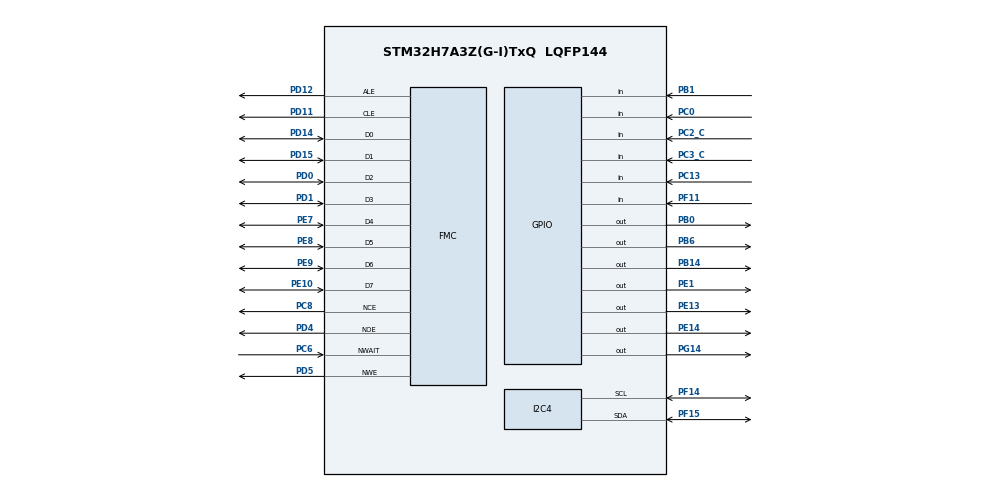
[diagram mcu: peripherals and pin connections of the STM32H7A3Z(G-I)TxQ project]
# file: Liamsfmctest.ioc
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CORTEX_M7.default_mode_Activation=1
Mcu.Family=STM32H7
Mcu.Name=STM32H7A3Z(G-I)TxQ
Mcu.Package=LQFP144
NUCLEO-H7A3ZI-Q.BUTTON=1
NUCLEO-H7A3ZI-Q.LD1=true
NUCLEO-H7A3ZI-Q.LD2=true
NUCLEO-H7A3ZI-Q.LD3=true
NUCLEO-H7A3ZI-Q.VCP=true
NVIC.EXTI15_10_IRQn=true\:0\:0\:false\:false\:true\:false\:true\:true
NVIC.PriorityGroup=NVIC_PRIORITYGROUP_4
PB0.Signal=GPIO_Output
PB1.GPIO_PuPd=GPIO_PULLUP
PB1.Signal=GPIO_Input
PB14.Signal=GPIO_Output
PB6.Signal=GPIO_Output
PC0.GPIO_PuPd=GPIO_PULLUP
PC0.Signal=GPIO_Input
PC13.Signal=GPIO_Input
PC14-OSC32_IN.GPIO_Label=OSC32_IN
PC14-OSC32_IN.Signal=RCC_OSC32_IN
PC15-OSC32_OUT.GPIO_Label=OSC32_OUT
PC15-OSC32_OUT.Signal=RCC_OSC32_OUT
PC2_C.GPIO_PuPd=GPIO_PULLUP
PC2_C.Signal=GPIO_Input
PC3_C.GPIO_PuPd=GPIO_PULLUP
PC3_C.Signal=GPIO_Input
PC6.Signal=FMC_NWAIT
PC8.Mode=NandChipSelect3_1
PC8.Signal=FMC_NCE
PD0.Signal=FMC_D2_DA2
PD1.Signal=FMC_D3_DA3
PD11.Signal=FMC_A16_CLE
PD12.Signal=FMC_A17_ALE
PD14.Signal=FMC_D0_DA0
PD15.Signal=FMC_D1_DA1
PD4.Signal=FMC_NOE
PD5.Signal=FMC_NWE
PD8.Signal=USART3_TX
PD9.Signal=USART3_RX
PE1.Signal=GPIO_Output
PE10.Signal=FMC_D7_DA7
PE13.Signal=GPIO_Output
PE14.Signal=GPIO_Output
PE7.Signal=FMC_D4_DA4
PE8.Signal=FMC_D5_DA5
PE9.Signal=FMC_D6_DA6
PF11.GPIO_PuPd=GPIO_PULLUP
PF11.Signal=GPIO_Input
PF14.Mode=I2C
PF14.Signal=I2C4_SCL
PF15.Mode=I2C
PF15.Signal=I2C4_SDA
PG14.Signal=GPIO_Output
PH0-OSC_IN.GPIO_Label=PH0-MCU
PH0-OSC_IN.Signal=RCC_OSC_IN
PH1-OSC_OUT.GPIO_Label=PH1-MCU
PH1-OSC_OUT.Signal=RCC_OSC_OUT
ProjectManager.HeapSize=0x200
ProjectManager.StackSize=0x400
ProjectManager.TargetToolchain=STM32CubeIDE
RCC.ADCFreq_Value=129000000
RCC.APB1Freq_Value=64000000
RCC.APB2Freq_Value=64000000
RCC.APB3Freq_Value=64000000
RCC.APB4Freq_Value=64000000
RCC.CortexFreq_Value=64000000
RCC.DIVM1=4
RCC.DIVM3=1
RCC.DIVN1=8
RCC.DIVN3=24
RCC.DIVQ1=4
RCC.HCLKFreq_Value=64000000
RCC.HSE_VALUE=8000000
RCC.PLLFRACN=0
RCC.PWR_Regulator_Voltage_Scale=PWR_REGULATOR_VOLTAGE_SCALE0
RCC.SYSCLKFreq_VALUE=64000000
RCC.SYSCLKSource=RCC_SYSCLKSOURCE_PLLCLK
RCC.SupplySource=PWR_DIRECT_SMPS_SUPPLY
RCC.USBCLockSelection=RCC_USBCLKSOURCE_HSI48
RCC.USBFreq_Value=48000000
SH.FMC_A16_CLE.0=FMC_CLE,8b-dmux1
SH.FMC_A17_ALE.0=FMC_ALE,8b-dmux1
SH.FMC_D0_DA0.0=FMC_D0,8b-dmux1
SH.FMC_D1_DA1.0=FMC_D1,8b-dmux1
SH.FMC_D2_DA2.0=FMC_D2,8b-dmux1
SH.FMC_D3_DA3.0=FMC_D3,8b-dmux1
SH.FMC_D4_DA4.0=FMC_D4,8b-dmux1
SH.FMC_D5_DA5.0=FMC_D5,8b-dmux1
SH.FMC_D6_DA6.0=FMC_D6,8b-dmux1
SH.FMC_D7_DA7.0=FMC_D7,8b-dmux1
SH.FMC_NOE.0=FMC_NOE,8b-dmux1
SH.FMC_NWAIT.0=FMC_NWAIT,Wait1
SH.FMC_NWE.0=FMC_NWE,8b-dmux1
VP_MEMORYMAP_VS_MEMORYMAP.Mode=CurAppReg
VP_NUCLEO-H7A3ZI-Q_VS_BSP_COMMON.Mode=COMMON
board=NUCLEO-H7A3ZI-Q

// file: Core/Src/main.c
/* USER CODE BEGIN Header */
/**
  ******************************************************************************
  * @file           : main.c
  * @brief          : Main program body
  ******************************************************************************
  * @attention
  *
  * Copyright (c) 2024 STMicroelectronics.
  * All rights reserved.
  *
  * This software is licensed under terms that can be found in the LICENSE file
  * in the root directory of this software component.
  * If no LICENSE file comes with this software, it is provided AS-IS.
  *
  ******************************************************************************
  */
/* USER CODE END Header */
#include "main.h"

/* USER CODE BEGIN Includes */
#define FLASH_COMMON_BANK_ADDR            0x80000000
#define FLASH_ATTRIBUTE_BANK_ADDR        0x88000000
#define FLASH_DATA_OFFSET                0x00000000
#define FLASH_COMMAND_OFFSET            0x01000000
#define FLASH_ADDRESS_OFFSET            0x02000000
/* USER CODE END Includes */

COM_InitTypeDef BspCOMInit;

I2C_HandleTypeDef hi2c4;

NAND_HandleTypeDef hnand1;

void SystemClock_Config(void);
static void MPU_Config(void);
static void MX_GPIO_Init(void);
static void MX_I2C4_Init(void);
static void MX_FMC_Init(void);

int main(void)
{

  /* MPU Configuration--------------------------------------------------------*/
  MPU_Config();

  /* MCU Configuration--------------------------------------------------------*/

  /* Reset of all peripherals, Initializes the Flash interface and the Systick. */
  HAL_Init();

  /* Configure the system clock */
  SystemClock_Config();

  /* Initialize all configured peripherals */
  MX_GPIO_Init();
  MX_I2C4_Init();
  MX_FMC_Init();

  /* Initialize leds */
  BSP_LED_Init(LED_GREEN);
  BSP_LED_Init(LED_YELLOW);
  BSP_LED_Init(LED_RED);

  /* Initialize USER push-button, will be used to trigger an interrupt each time it's pressed.*/
  BSP_PB_Init(BUTTON_USER, BUTTON_MODE_EXTI);

  /* Initialize COM1 port (115200, 8 bits (7-bit data + 1 stop bit), no parity */
  BspCOMInit.BaudRate   = 115200;
  BspCOMInit.WordLength = COM_WORDLENGTH_8B;
  BspCOMInit.StopBits   = COM_STOPBITS_1;
  BspCOMInit.Parity     = COM_PARITY_NONE;
  BspCOMInit.HwFlowCtl  = COM_HWCONTROL_NONE;
  if (BSP_COM_Init(COM1, &BspCOMInit) != BSP_ERROR_NONE)
  {
    Error_Handler();
  }

  /* Infinite loop */
  /* USER CODE BEGIN WHILE */
  while (1)
  {
	  *(__IO uint32_t*) (FLASH_COMMON_BANK_ADDR + FLASH_DATA_OFFSET) = 42;
    /* USER CODE END WHILE */

  }
}

void SystemClock_Config(void)
{
  RCC_OscInitTypeDef RCC_OscInitStruct = {0};
  RCC_ClkInitTypeDef RCC_ClkInitStruct = {0};

  /*AXI clock gating */
  RCC->CKGAENR = 0xFFFFFFFF;

  /** Supply configuration update enable
  */
  HAL_PWREx_ConfigSupply(PWR_DIRECT_SMPS_SUPPLY);

  /** Configure the main internal regulator output voltage
  */
  __HAL_PWR_VOLTAGESCALING_CONFIG(PWR_REGULATOR_VOLTAGE_SCALE0);

  while(!__HAL_PWR_GET_FLAG(PWR_FLAG_VOSRDY)) {}

  /** Initializes the RCC Oscillators according to the specified parameters
  * in the RCC_OscInitTypeDef structure.
  */
  RCC_OscInitStruct.OscillatorType = RCC_OSCILLATORTYPE_HSI;
  RCC_OscInitStruct.HSIState = RCC_HSI_DIV1;
  RCC_OscInitStruct.HSICalibrationValue = 64;
  RCC_OscInitStruct.PLL.PLLState = RCC_PLL_ON;
  RCC_OscInitStruct.PLL.PLLSource = RCC_PLLSOURCE_HSI;
  RCC_OscInitStruct.PLL.PLLM = 4;
  RCC_OscInitStruct.PLL.PLLN = 8;
  RCC_OscInitStruct.PLL.PLLP = 2;
  RCC_OscInitStruct.PLL.PLLQ = 4;
  RCC_OscInitStruct.PLL.PLLR = 2;
  RCC_OscInitStruct.PLL.PLLRGE = RCC_PLL1VCIRANGE_3;
  RCC_OscInitStruct.PLL.PLLVCOSEL = RCC_PLL1VCOWIDE;
  RCC_OscInitStruct.PLL.PLLFRACN = 0;
  if (HAL_RCC_OscConfig(&RCC_OscInitStruct) != HAL_OK)
  {
    Error_Handler();
  }

  /** Initializes the CPU, AHB and APB buses clocks
  */
  RCC_ClkInitStruct.ClockType = RCC_CLOCKTYPE_HCLK|RCC_CLOCKTYPE_SYSCLK
                              |RCC_CLOCKTYPE_PCLK1|RCC_CLOCKTYPE_PCLK2
                              |RCC_CLOCKTYPE_D3PCLK1|RCC_CLOCKTYPE_D1PCLK1;
  RCC_ClkInitStruct.SYSCLKSource = RCC_SYSCLKSOURCE_PLLCLK;
  RCC_ClkInitStruct.SYSCLKDivider = RCC_SYSCLK_DIV1;
  RCC_ClkInitStruct.AHBCLKDivider = RCC_HCLK_DIV1;
  RCC_ClkInitStruct.APB3CLKDivider = RCC_APB3_DIV1;
  RCC_ClkInitStruct.APB1CLKDivider = RCC_APB1_DIV1;
  RCC_ClkInitStruct.APB2CLKDivider = RCC_APB2_DIV1;
  RCC_ClkInitStruct.APB4CLKDivider = RCC_APB4_DIV1;

  if (HAL_RCC_ClockConfig(&RCC_ClkInitStruct, FLASH_LATENCY_1) != HAL_OK)
  {
    Error_Handler();
  }
}

static void MX_I2C4_Init(void)
{

  hi2c4.Instance = I2C4;
  hi2c4.Init.Timing = 0x10707DBC;
  hi2c4.Init.OwnAddress1 = 0;
  hi2c4.Init.AddressingMode = I2C_ADDRESSINGMODE_7BIT;
  hi2c4.Init.DualAddressMode = I2C_DUALADDRESS_DISABLE;
  hi2c4.Init.OwnAddress2 = 0;
  hi2c4.Init.OwnAddress2Masks = I2C_OA2_NOMASK;
  hi2c4.Init.GeneralCallMode = I2C_GENERALCALL_DISABLE;
  hi2c4.Init.NoStretchMode = I2C_NOSTRETCH_DISABLE;
  if (HAL_I2C_Init(&hi2c4) != HAL_OK)
  {
    Error_Handler();
  }

  /** Configure Analogue filter
  */
  if (HAL_I2CEx_ConfigAnalogFilter(&hi2c4, I2C_ANALOGFILTER_ENABLE) != HAL_OK)
  {
    Error_Handler();
  }

  /** Configure Digital filter
  */
  if (HAL_I2CEx_ConfigDigitalFilter(&hi2c4, 0) != HAL_OK)
  {
    Error_Handler();
  }

}

/* FMC initialization function */
static void MX_FMC_Init(void)
{

  FMC_NAND_PCC_TimingTypeDef ComSpaceTiming = {0};
  FMC_NAND_PCC_TimingTypeDef AttSpaceTiming = {0};

  /** Perform the NAND1 memory initialization sequence
  */
  hnand1.Instance = FMC_NAND_DEVICE;
  /* hnand1.Init */
  hnand1.Init.NandBank = FMC_NAND_BANK3;
  hnand1.Init.Waitfeature = FMC_NAND_WAIT_FEATURE_ENABLE;
  hnand1.Init.MemoryDataWidth = FMC_NAND_MEM_BUS_WIDTH_8;
  hnand1.Init.EccComputation = FMC_NAND_ECC_DISABLE;
  hnand1.Init.ECCPageSize = FMC_NAND_ECC_PAGE_SIZE_256BYTE;
  hnand1.Init.TCLRSetupTime = 0;
  hnand1.Init.TARSetupTime = 0;
  /* hnand1.Config */
  hnand1.Config.PageSize = 0;
  hnand1.Config.SpareAreaSize = 0;
  hnand1.Config.BlockSize = 0;
  hnand1.Config.BlockNbr = 0;
  hnand1.Config.PlaneNbr = 0;
  hnand1.Config.PlaneSize = 0;
  hnand1.Config.ExtraCommandEnable = DISABLE;
  /* ComSpaceTiming */
  ComSpaceTiming.SetupTime = 252;
  ComSpaceTiming.WaitSetupTime = 252;
  ComSpaceTiming.HoldSetupTime = 252;
  ComSpaceTiming.HiZSetupTime = 252;
  /* AttSpaceTiming */
  AttSpaceTiming.SetupTime = 252;
  AttSpaceTiming.WaitSetupTime = 252;
  AttSpaceTiming.HoldSetupTime = 252;
  AttSpaceTiming.HiZSetupTime = 252;

  if (HAL_NAND_Init(&hnand1, &ComSpaceTiming, &AttSpaceTiming) != HAL_OK)
  {
    Error_Handler( );
  }

}

static void MX_GPIO_Init(void)
{
  GPIO_InitTypeDef GPIO_InitStruct = {0};

  /* GPIO Ports Clock Enable */
  __HAL_RCC_GPIOC_CLK_ENABLE();
  __HAL_RCC_GPIOH_CLK_ENABLE();
  __HAL_RCC_GPIOB_CLK_ENABLE();
  __HAL_RCC_GPIOF_CLK_ENABLE();
  __HAL_RCC_GPIOE_CLK_ENABLE();
  __HAL_RCC_GPIOD_CLK_ENABLE();
  __HAL_RCC_GPIOG_CLK_ENABLE();

  /*Configure GPIO pin Output Level */
  HAL_GPIO_WritePin(GPIOE, GPIO_PIN_13|GPIO_PIN_14, GPIO_PIN_RESET);

  /*Configure GPIO pin Output Level */
  HAL_GPIO_WritePin(GPIOG, GPIO_PIN_14, GPIO_PIN_RESET);

  /*Configure GPIO pin Output Level */
  HAL_GPIO_WritePin(GPIOB, GPIO_PIN_6, GPIO_PIN_RESET);

  /*Configure GPIO pins : PC0 PC2 PC3 */
  GPIO_InitStruct.Pin = GPIO_PIN_0|GPIO_PIN_2|GPIO_PIN_3;
  GPIO_InitStruct.Mode = GPIO_MODE_INPUT;
  GPIO_InitStruct.Pull = GPIO_PULLUP;
  HAL_GPIO_Init(GPIOC, &GPIO_InitStruct);

  /*Configure GPIO pin : PB1 */
  GPIO_InitStruct.Pin = GPIO_PIN_1;
  GPIO_InitStruct.Mode = GPIO_MODE_INPUT;
  GPIO_InitStruct.Pull = GPIO_PULLUP;
  HAL_GPIO_Init(GPIOB, &GPIO_InitStruct);

  /*Configure GPIO pin : PF11 */
  GPIO_InitStruct.Pin = GPIO_PIN_11;
  GPIO_InitStruct.Mode = GPIO_MODE_INPUT;
  GPIO_InitStruct.Pull = GPIO_PULLUP;
  HAL_GPIO_Init(GPIOF, &GPIO_InitStruct);

  /*Configure GPIO pins : PE13 PE14 */
  GPIO_InitStruct.Pin = GPIO_PIN_13|GPIO_PIN_14;
  GPIO_InitStruct.Mode = GPIO_MODE_OUTPUT_PP;
  GPIO_InitStruct.Pull = GPIO_NOPULL;
  GPIO_InitStruct.Speed = GPIO_SPEED_FREQ_LOW;
  HAL_GPIO_Init(GPIOE, &GPIO_InitStruct);

  /*Configure GPIO pin : PG14 */
  GPIO_InitStruct.Pin = GPIO_PIN_14;
  GPIO_InitStruct.Mode = GPIO_MODE_OUTPUT_PP;
  GPIO_InitStruct.Pull = GPIO_NOPULL;
  GPIO_InitStruct.Speed = GPIO_SPEED_FREQ_LOW;
  HAL_GPIO_Init(GPIOG, &GPIO_InitStruct);

  /*Configure GPIO pin : PB6 */
  GPIO_InitStruct.Pin = GPIO_PIN_6;
  GPIO_InitStruct.Mode = GPIO_MODE_OUTPUT_PP;
  GPIO_InitStruct.Pull = GPIO_NOPULL;
  GPIO_InitStruct.Speed = GPIO_SPEED_FREQ_LOW;
  HAL_GPIO_Init(GPIOB, &GPIO_InitStruct);

}

 /* MPU Configuration */

void MPU_Config(void)
{
  MPU_Region_InitTypeDef MPU_InitStruct = {0};

  /* Disables the MPU */
  HAL_MPU_Disable();

  /** Initializes and configures the Region and the memory to be protected
  */
  MPU_InitStruct.Enable = MPU_REGION_ENABLE;
  MPU_InitStruct.Number = MPU_REGION_NUMBER0;
  MPU_InitStruct.BaseAddress = 0x0;
  MPU_InitStruct.Size = MPU_REGION_SIZE_4GB;
  MPU_InitStruct.SubRegionDisable = 0x87;
  MPU_InitStruct.TypeExtField = MPU_TEX_LEVEL0;
  MPU_InitStruct.AccessPermission = MPU_REGION_NO_ACCESS;
  MPU_InitStruct.DisableExec = MPU_INSTRUCTION_ACCESS_DISABLE;
  MPU_InitStruct.IsShareable = MPU_ACCESS_SHAREABLE;
  MPU_InitStruct.IsCacheable = MPU_ACCESS_NOT_CACHEABLE;
  MPU_InitStruct.IsBufferable = MPU_ACCESS_NOT_BUFFERABLE;

  HAL_MPU_ConfigRegion(&MPU_InitStruct);
  /* Enables the MPU */
  HAL_MPU_Enable(MPU_PRIVILEGED_DEFAULT);

}

void Error_Handler(void)
{
  __disable_irq();
  while (1)
  {
  }
}
